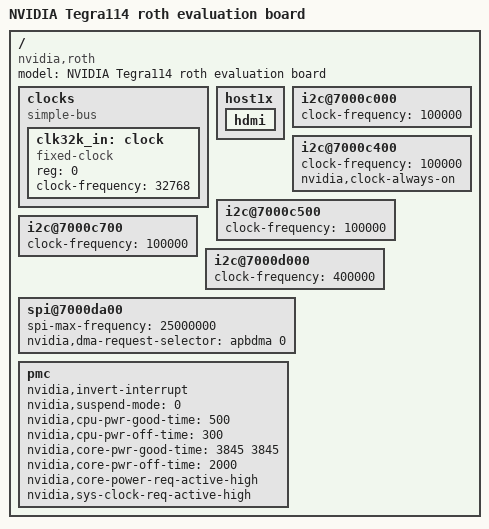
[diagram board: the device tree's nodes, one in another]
/dts-v1/;

/include/ "tegra114.dtsi"

/ {
	model = "NVIDIA Tegra114 roth evaluation board";
	compatible = "nvidia,roth", "nvidia,tegra114";

	clocks {
		compatible = "simple-bus";
		#address-cells = <1>;
		#size-cells = <0>;

		clk32k_in: clock {
			compatible = "fixed-clock";
			reg=<0>;
			#clock-cells = <0>;
			clock-frequency = <32768>;
		};
	};

	host1x {
		hdmi {
			status = "okay";
		};
	};

	i2c@7000c000 {
		status = "okay";
		clock-frequency = <100000>;
	};

	i2c@7000c400 {
		status = "okay";
		clock-frequency = <100000>;
		nvidia,clock-always-on;
	};

	i2c@7000c500 {
		status = "okay";
		clock-frequency = <100000>;
	};

	i2c@7000c700 {
		status = "okay";
		clock-frequency = <100000>;
	};

	i2c@7000d000 {
		status = "okay";
		clock-frequency = <400000>;
	};

	spi@7000da00 {
		status = "okay";
		spi-max-frequency = <25000000>;
		nvidia,dma-request-selector = <&apbdma 0>;
	};

	pmc {
		status = "okay";
		nvidia,invert-interrupt;
		nvidia,suspend-mode = <0>;
		nvidia,cpu-pwr-good-time = <500>;
		nvidia,cpu-pwr-off-time = <300>;
		nvidia,core-pwr-good-time = <3845 3845>;
		nvidia,core-pwr-off-time = <2000>;
		nvidia,core-power-req-active-high;
		nvidia,sys-clock-req-active-high;
	};
};
